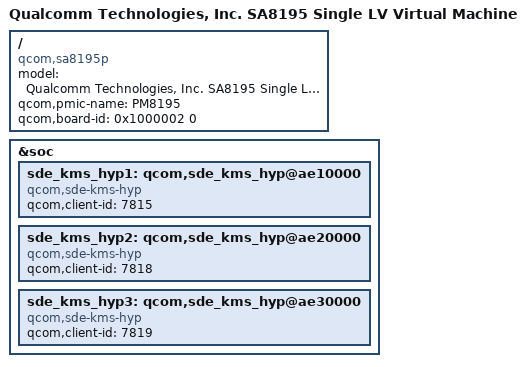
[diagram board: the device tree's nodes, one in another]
/* Copyright (c) 2020, The Linux Foundation. All rights reserved.
 *
 * This program is free software; you can redistribute it and/or modify
 * it under the terms of the GNU General Public License version 2 and
 * only version 2 as published by the Free Software Foundation.
 *
 * This program is distributed in the hope that it will be useful,
 * but WITHOUT ANY WARRANTY; without even the implied warranty of
 * MERCHANTABILITY or FITNESS FOR A PARTICULAR PURPOSE.  See the
 * GNU General Public License for more details.
 */

/dts-v1/;

#include "sa8195-vm.dtsi"
#include "sa8195-vm-lv-lxc.dtsi"

/ {
	model = "Qualcomm Technologies, Inc. SA8195 Single LV Virtual Machine";
	compatible = "qcom,sa8195p";
	qcom,pmic-name = "PM8195";
	qcom,board-id = <0x1000002 0>;
};

&soc {
	sde_kms_hyp1: qcom,sde_kms_hyp@ae10000 {
		compatible = "qcom,sde-kms-hyp";
		qcom,client-id = "7815";
	};

	sde_kms_hyp2: qcom,sde_kms_hyp@ae20000 {
		compatible = "qcom,sde-kms-hyp";
		qcom,client-id = "7818";
	};

	sde_kms_hyp3: qcom,sde_kms_hyp@ae30000 {
		compatible = "qcom,sde-kms-hyp";
		qcom,client-id = "7819";
	};
};
